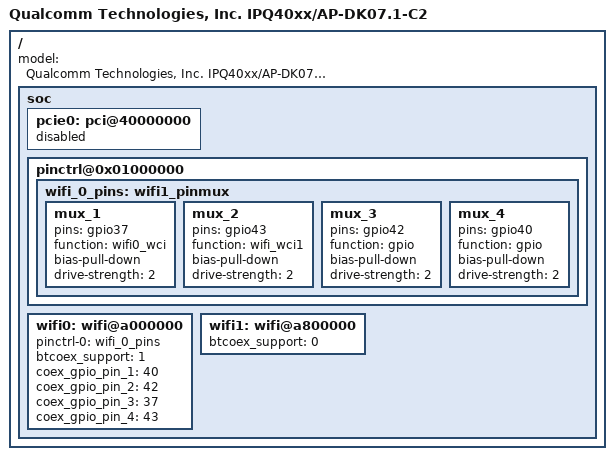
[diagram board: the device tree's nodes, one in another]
/* Copyright (c) 2016, The Linux Foundation. All rights reserved.
 *
 * Permission to use, copy, modify, and/or distribute this software for any
 * purpose with or without fee is hereby granted, provided that the above
 * copyright notice and this permission notice appear in all copies.
 *
 * THE SOFTWARE IS PROVIDED "AS IS" AND THE AUTHOR DISCLAIMS ALL WARRANTIES
 * WITH REGARD TO THIS SOFTWARE INCLUDING ALL IMPLIED WARRANTIES OF
 * MERCHANTABILITY AND FITNESS. IN NO EVENT SHALL THE AUTHOR BE LIABLE FOR
 * ANY SPECIAL, DIRECT, INDIRECT, OR CONSEQUENTIAL DAMAGES OR ANY DAMAGES
 * WHATSOEVER RESULTING FROM LOSS OF USE, DATA OR PROFITS, WHETHER IN AN
 * ACTION OF CONTRACT, NEGLIGENCE OR OTHER TORTIOUS ACTION, ARISING OUT OF
 * OR IN CONNECTION WITH THE USE OR PERFORMANCE OF THIS SOFTWARE.
 *
 */

#include "qcom-ipq4019-ap.dk07.1.dtsi"

/ {
	model = "Qualcomm Technologies, Inc. IPQ40xx/AP-DK07.1-C2";

	soc {
		pcie0: pci@40000000 {
			status = "disabled";
		};

		pinctrl@0x01000000 {
			wifi_0_pins: wifi1_pinmux {
				mux_1 {
					pins = "gpio37";
					function="wifi0_wci";
					bias-pull-down;
					drive-strength = <2>;
				};
				mux_2 {
					pins = "gpio43";
					function="wifi_wci1";
					bias-pull-down;
					drive-strength = <2>;
				};
				mux_3 {
					pins = "gpio42";
					function="gpio";
					bias-pull-down;
					drive-strength = <2>;
				};
				mux_4 {
					pins = "gpio40";
					function="gpio";
					bias-pull-down;
					drive-strength = <2>;
				};
			};
		};

		wifi0: wifi@a000000 {
			pinctrl-0 = <&wifi_0_pins>;
			pinctrl-names = "default";
			btcoex_support = <1>;
			coex_gpio_pin_1 = <40>;
			coex_gpio_pin_2 = <42>;
			coex_gpio_pin_3 = <37>;
			coex_gpio_pin_4 = <43>;
		};

		wifi1: wifi@a800000 {
			btcoex_support = <0>;
		};
	};
};
